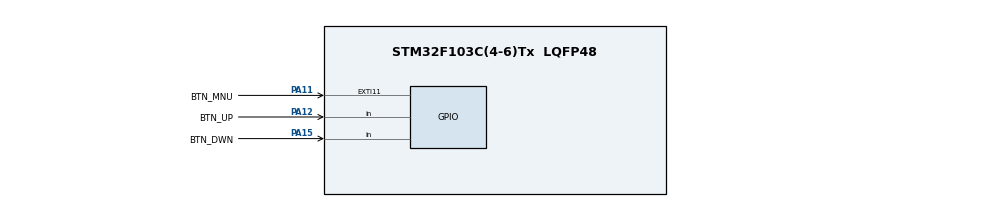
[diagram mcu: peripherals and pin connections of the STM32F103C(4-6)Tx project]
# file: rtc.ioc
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Mcu.Family=STM32F1
Mcu.Name=STM32F103C(4-6)Tx
Mcu.Package=LQFP48
NVIC.EXTI15_10_IRQn=true\:0\:0\:false\:false\:true\:true
NVIC.PriorityGroup=NVIC_PRIORITYGROUP_4
PA11.GPIO_Label=BTN_MNU
PA11.GPIO_ModeDefaultEXTI=GPIO_MODE_IT_FALLING
PA11.Signal=GPXTI11
PA12.GPIO_Label=BTN_UP
PA12.Signal=GPIO_Input
PA13.Mode=Serial_Wire
PA13.Signal=SYS_JTMS-SWDIO
PA14.Mode=Serial_Wire
PA14.Signal=SYS_JTCK-SWCLK
PA15.GPIO_Label=BTN_DWN
PA15.Signal=GPIO_Input
ProjectManager.HeapSize=0x200
ProjectManager.StackSize=0x400
ProjectManager.TargetToolchain=MDK-ARM V5
RCC.APB1Freq_Value=8000000
RCC.APB2Freq_Value=8000000
RTC.Date=22
RTC.Hours=19
RTC.Minutes=8
RTC.Month=RTC_MONTH_NOVEMBER
RTC.WeekDay=RTC_WEEKDAY_THURSDAY
RTC.Year=18
VP_RTC_VS_RTC_Activate.Mode=RTC_Enabled
VP_RTC_VS_RTC_Calendar.Mode=RTC_Calendar
board=custom

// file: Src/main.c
/**
  ******************************************************************************
  * @file           : main.c
  * @brief          : Main program body
  ******************************************************************************
  ** This notice applies to any and all portions of this file
  * that are not between comment pairs USER CODE BEGIN and
  * USER CODE END. Other portions of this file, whether
  * inserted by the user or by software development tools
  * are owned by their respective copyright owners.
  *
  * COPYRIGHT(c) 2018 STMicroelectronics
  *
  * Redistribution and use in source and binary forms, with or without modification,
  * are permitted provided that the following conditions are met:
  *   1. Redistributions of source code must retain the above copyright notice,
  *      this list of conditions and the following disclaimer.
  *   2. Redistributions in binary form must reproduce the above copyright notice,
  *      this list of conditions and the following disclaimer in the documentation
  *      and/or other materials provided with the distribution.
  *   3. Neither the name of STMicroelectronics nor the names of its contributors
  *      may be used to endorse or promote products derived from this software
  *      without specific prior written permission.
  *
  * THIS SOFTWARE IS PROVIDED BY THE COPYRIGHT HOLDERS AND CONTRIBUTORS "AS IS"
  * AND ANY EXPRESS OR IMPLIED WARRANTIES, INCLUDING, BUT NOT LIMITED TO, THE
  * IMPLIED WARRANTIES OF MERCHANTABILITY AND FITNESS FOR A PARTICULAR PURPOSE ARE
  * DISCLAIMED. IN NO EVENT SHALL THE COPYRIGHT HOLDER OR CONTRIBUTORS BE LIABLE
  * FOR ANY DIRECT, INDIRECT, INCIDENTAL, SPECIAL, EXEMPLARY, OR CONSEQUENTIAL
  * DAMAGES (INCLUDING, BUT NOT LIMITED TO, PROCUREMENT OF SUBSTITUTE GOODS OR
  * SERVICES; LOSS OF USE, DATA, OR PROFITS; OR BUSINESS INTERRUPTION) HOWEVER
  * CAUSED AND ON ANY THEORY OF LIABILITY, WHETHER IN CONTRACT, STRICT LIABILITY,
  * OR TORT (INCLUDING NEGLIGENCE OR OTHERWISE) ARISING IN ANY WAY OUT OF THE USE
  * OF THIS SOFTWARE, EVEN IF ADVISED OF THE POSSIBILITY OF SUCH DAMAGE.
  *
  ******************************************************************************
  */
#include "main.h"
#include "stm32f1xx_hal.h"

/* USER CODE BEGIN Includes */

#include "textLCD.h"

/* USER CODE END Includes */

RTC_HandleTypeDef hrtc;

/* USER CODE BEGIN PV */
/* Private variables ---------------------------------------------------------*/

RTC_TimeTypeDef thoiGian;
RTC_DateTypeDef ngayThang;
char lcdBuffer[32];

/* USER CODE END PV */

void SystemClock_Config(void);
static void MX_GPIO_Init(void);
static void MX_RTC_Init(void);

/* USER CODE BEGIN PFP */
/* Private function prototypes -----------------------------------------------*/

/* USER CODE END PFP */

int main(void)
{

  /* MCU Configuration----------------------------------------------------------*/

  /* Reset of all peripherals, Initializes the Flash interface and the Systick. */
  HAL_Init();

  /* Configure the system clock */
  SystemClock_Config();

  /* Initialize all configured peripherals */
  MX_GPIO_Init();
  MX_RTC_Init();
  /* USER CODE BEGIN 2 */

  lcd_init();
  lcd_puts(" Thoi Gian Thuc ");
  HAL_Delay(1000);
  lcd_cmd(0x01);

  /* USER CODE END 2 */

  /* Infinite loop */
  /* USER CODE BEGIN WHILE */
  while (1)
  {
    HAL_RTC_GetTime(&hrtc, &thoiGian, RTC_FORMAT_BIN);
    HAL_RTC_GetDate(&hrtc, &ngayThang, RTC_FORMAT_BIN);

    lcd_gotoxy(5,1);

    // Hiển thị giờ
    sprintf(lcdBuffer, "%02d", thoiGian.Hours);
    lcd_puts(lcdBuffer);
    lcd_puts(":");

    // Hiển thị phút
    sprintf(lcdBuffer, "%02d", thoiGian.Minutes);
    lcd_puts(lcdBuffer);
    lcd_puts(":");

    // Hiển thị giây
    sprintf(lcdBuffer, "%02d", thoiGian.Seconds);
    lcd_puts(lcdBuffer);

    lcd_gotoxy(4,2);

    // Hiển thị ngày
    sprintf(lcdBuffer, "%02d", ngayThang.Date);
    lcd_puts(lcdBuffer);
    lcd_puts("/");

    // Hiển thị tháng
    sprintf(lcdBuffer, "%02d", ngayThang.Month);
    lcd_puts(lcdBuffer);
    lcd_puts("/");

    // Hiển thị năm
    sprintf(lcdBuffer, "20%02d", ngayThang.Year);
    lcd_puts(lcdBuffer);

    HAL_Delay(100);

  /* USER CODE END WHILE */

  }

}

void SystemClock_Config(void)
{

  RCC_OscInitTypeDef RCC_OscInitStruct;
  RCC_ClkInitTypeDef RCC_ClkInitStruct;
  RCC_PeriphCLKInitTypeDef PeriphClkInit;

    /**Initializes the CPU, AHB and APB busses clocks
    */
  RCC_OscInitStruct.OscillatorType = RCC_OSCILLATORTYPE_HSI|RCC_OSCILLATORTYPE_LSI;
  RCC_OscInitStruct.HSIState = RCC_HSI_ON;
  RCC_OscInitStruct.HSICalibrationValue = 16;
  RCC_OscInitStruct.LSIState = RCC_LSI_ON;
  RCC_OscInitStruct.PLL.PLLState = RCC_PLL_NONE;
  if (HAL_RCC_OscConfig(&RCC_OscInitStruct) != HAL_OK)
  {
    _Error_Handler(__FILE__, __LINE__);
  }

    /**Initializes the CPU, AHB and APB busses clocks
    */
  RCC_ClkInitStruct.ClockType = RCC_CLOCKTYPE_HCLK|RCC_CLOCKTYPE_SYSCLK
                              |RCC_CLOCKTYPE_PCLK1|RCC_CLOCKTYPE_PCLK2;
  RCC_ClkInitStruct.SYSCLKSource = RCC_SYSCLKSOURCE_HSI;
  RCC_ClkInitStruct.AHBCLKDivider = RCC_SYSCLK_DIV1;
  RCC_ClkInitStruct.APB1CLKDivider = RCC_HCLK_DIV1;
  RCC_ClkInitStruct.APB2CLKDivider = RCC_HCLK_DIV1;

  if (HAL_RCC_ClockConfig(&RCC_ClkInitStruct, FLASH_LATENCY_0) != HAL_OK)
  {
    _Error_Handler(__FILE__, __LINE__);
  }

  PeriphClkInit.PeriphClockSelection = RCC_PERIPHCLK_RTC;
  PeriphClkInit.RTCClockSelection = RCC_RTCCLKSOURCE_LSI;
  if (HAL_RCCEx_PeriphCLKConfig(&PeriphClkInit) != HAL_OK)
  {
    _Error_Handler(__FILE__, __LINE__);
  }

    /**Configure the Systick interrupt time
    */
  HAL_SYSTICK_Config(HAL_RCC_GetHCLKFreq()/1000);

    /**Configure the Systick
    */
  HAL_SYSTICK_CLKSourceConfig(SYSTICK_CLKSOURCE_HCLK);

  /* SysTick_IRQn interrupt configuration */
  HAL_NVIC_SetPriority(SysTick_IRQn, 0, 0);
}

/* RTC init function */
static void MX_RTC_Init(void)
{

  RTC_TimeTypeDef sTime;
  RTC_DateTypeDef DateToUpdate;

    /**Initialize RTC Only
    */
  hrtc.Instance = RTC;
  hrtc.Init.AsynchPrediv = RTC_AUTO_1_SECOND;
  hrtc.Init.OutPut = RTC_OUTPUTSOURCE_ALARM;
  if (HAL_RTC_Init(&hrtc) != HAL_OK)
  {
    _Error_Handler(__FILE__, __LINE__);
  }

    /**Initialize RTC and set the Time and Date
    */
  sTime.Hours = 0x19;
  sTime.Minutes = 0x8;
  sTime.Seconds = 0x0;

  if (HAL_RTC_SetTime(&hrtc, &sTime, RTC_FORMAT_BCD) != HAL_OK)
  {
    _Error_Handler(__FILE__, __LINE__);
  }

  DateToUpdate.WeekDay = RTC_WEEKDAY_THURSDAY;
  DateToUpdate.Month = RTC_MONTH_NOVEMBER;
  DateToUpdate.Date = 0x22;
  DateToUpdate.Year = 0x18;

  if (HAL_RTC_SetDate(&hrtc, &DateToUpdate, RTC_FORMAT_BCD) != HAL_OK)
  {
    _Error_Handler(__FILE__, __LINE__);
  }

}

/** Configure pins as
        * Analog
        * Input
        * Output
        * EVENT_OUT
        * EXTI
*/
static void MX_GPIO_Init(void)
{

  GPIO_InitTypeDef GPIO_InitStruct;

  /* GPIO Ports Clock Enable */
  __HAL_RCC_GPIOA_CLK_ENABLE();
  __HAL_RCC_GPIOB_CLK_ENABLE();

  /*Configure GPIO pin : BTN_MNU_Pin */
  GPIO_InitStruct.Pin = BTN_MNU_Pin;
  GPIO_InitStruct.Mode = GPIO_MODE_IT_FALLING;
  GPIO_InitStruct.Pull = GPIO_NOPULL;
  HAL_GPIO_Init(BTN_MNU_GPIO_Port, &GPIO_InitStruct);

  /*Configure GPIO pins : BTN_UP_Pin BTN_DWN_Pin */
  GPIO_InitStruct.Pin = BTN_UP_Pin|BTN_DWN_Pin;
  GPIO_InitStruct.Mode = GPIO_MODE_INPUT;
  GPIO_InitStruct.Pull = GPIO_NOPULL;
  HAL_GPIO_Init(GPIOA, &GPIO_InitStruct);

  /* EXTI interrupt init*/
  HAL_NVIC_SetPriority(EXTI15_10_IRQn, 0, 0);
  HAL_NVIC_EnableIRQ(EXTI15_10_IRQn);

}

void _Error_Handler(char *file, int line)
{
  while(1)
  {
  }
}

/************************ (C) COPYRIGHT STMicroelectronics *****END OF FILE****/
